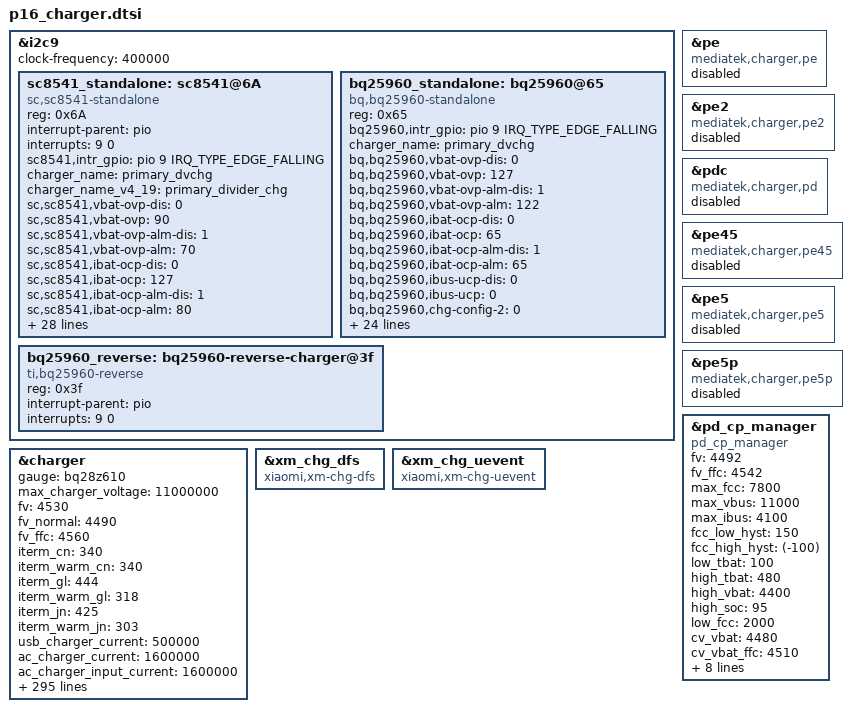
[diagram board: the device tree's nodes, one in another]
#include "mediatek/bq28z610_fg.dtsi"

&i2c9{
    clock-frequency = <400000>;
    sc8541_standalone: sc8541@6A{
        compatible = "sc,sc8541-standalone";
        #io-channel-cells = <1>;
        reg = <0x6A>;
		interrupt-parent = <&pio>;
		interrupts = <9 0>;
		sc8541,intr_gpio = <&pio 9 IRQ_TYPE_EDGE_FALLING>;
		charger_name = "primary_dvchg";
		charger_name_v4_19 = "primary_divider_chg";
		sc,sc8541,vbat-ovp-dis = <0>;
		sc,sc8541,vbat-ovp = <90>; /*3840 + val * 10*/
		sc,sc8541,vbat-ovp-alm-dis = <1>;
		sc,sc8541,vbat-ovp-alm = <70>; /*3840 + val * 10*/
		sc,sc8541,ibat-ocp-dis = <0>;
		sc,sc8541,ibat-ocp  = <127>; /*val * 100*/
		sc,sc8541,ibat-ocp-alm-dis = <1>;
		sc,sc8541,ibat-ocp-alm = <80>; /*val * 100*/
		sc,sc8541,ibus-ucp-dis = <0>;
		sc,sc8541,vbus-in-range-dis = <0>;
		sc,sc8541,vbus-pd-en = <0>;
		sc,sc8541,vbus-ovp = <127>; /*7000 + val * 50*/
		sc,sc8541,vbus-ovp-alm-dis = <1>;
		sc,sc8541,vbus-ovp-alm = <127>; /*7000 + val * 50*/
		sc,sc8541,ibus-ocp-dis = <0>;
		sc,sc8541,ibus-ocp = <21>; /*1000 + val * 250*/
		sc,sc8541,tshut-dis = <1>;
		sc,sc8541,tsbus-flt-dis = <1>;
		sc,sc8541,tsbat-flt-dis = <1>;
		sc,sc8541,tdie-alm = <200>; /*25 + val * 0.5*/
		sc,sc8541,tsbus-flt = <21>;
		sc,sc8541,tsbat-flt = <21>;
		sc,sc8541,vac1-ovp = <3>; /*0:6.5V 1:10.5V 2:12V 3:14V 4:16V 5~7:18V*/
		sc,sc8541,vac2-ovp = <3>; /*0:6.5V 1:10.5V 2:12V 3:14V 4:16V 5~7:18V*/
		sc,sc8541,vac1-pd-en = <0>;
		sc,sc8541,vac2-pd-en = <0>;
		sc,sc8541,fsw-set = <4>; /*0:200KHz 1:300KHz 2:400KHz
				3:500KHz 4:600KHz 5:650KHz 6:700KHz 7:750KHz*/
		sc,sc8541,wd-timeout = <0>; /*0:0.5s 1:1s 2:5s 3:30s*/
		sc,sc8541,wd-timeout-dis = <1>;
		sc,sc8541,ibat-sns-r = <0>; /*0:2mho 1:5mho*/
		sc,sc8541,ss-timeout = <7>; /*0:6.25ms 1:12.5ms 2:25ms 3:50ms
				4:100ms 5:400ms 6:1.5s 7:10s*/
		sc,sc8541,ibus-ucp-fall-dg = <1>;
		sc,sc8541,vout-ovp-dis = <0>;
		sc,sc8541,vout-ovp = <3>; /*4700 + val * 100*/
		sc,sc8541,pmid2out-uvp = <7>; /*50 + val * 25*/
		sc,sc8541,pmid2out-ovp = <7>; /*200 + val * 50*/
    };
    bq25960_standalone: bq25960@65 {
        compatible = "bq,bq25960-standalone";
        #io-channel-cells = <1>;
        status = "ok";
        reg = <0x65>;
        bq25960,intr_gpio = <&pio 9 IRQ_TYPE_EDGE_FALLING>;
        charger_name = "primary_dvchg";
        bq,bq25960,vbat-ovp-dis = <0>;
        bq,bq25960,vbat-ovp = <127>; /*3500 + val * 10*/
        bq,bq25960,vbat-ovp-alm-dis = <1>;
        bq,bq25960,vbat-ovp-alm = <122>; /*3500 + val * 10*/
        bq,bq25960,ibat-ocp-dis = <0>;
        bq,bq25960,ibat-ocp  = <65>; /*2000 + val * 100*/
        bq,bq25960,ibat-ocp-alm-dis = <1>;
        bq,bq25960,ibat-ocp-alm = <65>; /*2000 + val * 100*/
        bq,bq25960,ibus-ucp-dis = <0>;
        bq,bq25960,ibus-ucp = <0>;
        bq,bq25960,chg-config-2 = <0>;
        bq,bq25960,vbus-pd-en = <0>;
        bq,bq25960,vbus-ovp = <127>; /*7000 + val * 50*/
        bq,bq25960,vbus-ovp-alm-dis = <1>;
        bq,bq25960,vbus-ovp-alm = <127>; /*7000 + val * 50*/
        /*bq,bq25960,ibus-ocp-dis = <0>;*/
        bq,bq25960,ibus-ocp = <21>; /*1000 + val * 250*/
        /*bq,bq25960,tshut-dis = <1>;*/
        bq,bq25960,tshut-dis = <1>;//To be doublecheck
        bq,bq25960,tsbus-flt-dis = <1>;
        bq,bq25960,tsbat-flt-dis = <1>;
        bq,bq25960,tdie-alm = <200>; /*25 + val * 0.5*/
        bq,bq25960,tsbus-flt = <21>;
        bq,bq25960,tsbat-flt = <21>;
        bq,bq25960,vac1-ovp = <3>; /*0:6.5V 1:10.5V 2:12V 3:14V 4:16V 5~7:18V*/
        bq,bq25960,vac2-ovp = <3>; /*0:6.5V 1:10.5V 2:12V 3:14V 4:16V 5~7:18V*/
        bq,bq25960,vac1-pd-en = <0>;
        bq,bq25960,vac2-pd-en = <0>;
        bq,bq25960,fsw-set = <4>; /*0:187.5KHz 1:250KHz 2:300KHz
                                    3:375KHz 4:500KHz 5:750KHz */
        bq,bq25960,wd-timeout = <0>; /*0:0.5s 1:1s 2:5s 3:30s*/
        bq,bq25960,wd-timeout-dis = <1>;
        bq,bq25960,ibat-sns-r = <0>; /*0:2mho 1:5mho*/
        bq,bq25960,ss-timeout = <7>; /*0:6.25ms 1:12.5ms 2:25ms 3:50ms
                4:100ms 5:400ms 6:1.5s 7:10s*/
        bq,bq25960,ibus-ucp-fall-dg = <1>; /*0:0.01ms, 1:5ms, 2:50ms, 3:150ms*/
        bq,bq25960,vout-ovp-dis = <0>;
        bq,bq25960,ms = <0>;
        bq,bq25960,vout-ovp = <3>; /*4700 + val * 100*/
        /*bq,bq25960,pmid2out-uvp = <7>;*/ /*50 + val * 25*/
        /*bq,bq25960,pmid2out-ovp = <7>; */ /*150 + val * 50*/
    };

	bq25960_reverse: bq25960-reverse-charger@3f {
		status = "okay";
		#io-channel-cells = <1>;
		compatible = "ti,bq25960-reverse";
		reg = <0x3f>;
		interrupt-parent = <&pio>;
		interrupts = <9 0>;
	};
};
&pe {
	compatible = "mediatek,charger,pe";
    status = "disabled";
};
&pe2 {
    compatible = "mediatek,charger,pe2";
    status = "disabled";
};
&pdc {
    compatible = "mediatek,charger,pd";
    status = "disabled";
};
&pe45 {
    compatible = "mediatek,charger,pe45";
    status = "disabled";
};
&pe5 {
    compatible = "mediatek,charger,pe5";
    status = "disabled";
};
&pe5p {
    compatible = "mediatek,charger,pe5p";
    status = "disabled";
};
&charger {
		gauge = <&bq28z610>;
		max_charger_voltage = <11000000>;
		fv = <4530>;
		fv_normal = <4490>;
		fv_ffc = <4560>;
		iterm_cn = <340>;
		iterm_warm_cn = <340>;
		iterm_gl = <444>;
		iterm_warm_gl = <318>;
		iterm_jn = <425>;
		iterm_warm_jn = <303>;
		/* charging current */
		usb_charger_current = <500000>;
		ac_charger_current = <1600000>;
		ac_charger_input_current = <1600000>;
		charging_host_charger_current = <900000>;
		ffc_low_tbat = <230>;
		ffc_medium_tbat = <230>;
		ffc_warm_tbat = <350>;
		ffc_little_high_tbat = <400>;
		ffc_high_tbat = <450>;
		ffc_high_soc = <95>;
		step_fallback_hyst = <25>;
		step_forward_hyst = <5>;
		jeita_fallback_hyst = <10>;
		jeita_forward_hyst = <0>;
		min_charger_voltage_1 = <4600000>;
		min_charger_voltage_2 = <4500000>;
		mt6369_moscon1_control;
		disable-aicl = <1>;

		/* battery temperature protection */
		enable-min-charge-temp;
		min-charge-temp = <(-10)>;
		min-charge-temp-plus-x-degree = <(-8)>;
		max-charge-temp = <58>;
		max-charge-temp-minus-x-degree = <56>;

		en_floatgnd;

		jeita_fcc_cfg_cn = <(-100)	30	0	680	680
				31	80	4200	1360	1020
				81	130	4200	2040	1360
				131	180	4200	4760	3400
				181	230	0	5440	5440
				231	450	4070	8000	5400
				451	600	4100	3400	0>;

		jeita_fv_cfg_cn = <(-100)	30	4530
				31	80	4530
				81	130	4530
				131	180	4530
				181	230	4530
				231	450	4490
				451	600	4100>;
		/* 1-100cls */
		step_chg_cfg_1_cycle_cn_nvt = <2000	4100	8000
					4101	4200	6000
					4201	4560	5400>;
		step_chg_cfg_1_cycle_normal_cn_nvt = <2000	4070	8000
					4071	4490	5400
					4071	4490	5400>;
		step_chg_cfg_1_cycle_cn_swd = <2000	4070	8000
					4071	4170	6000
					4171	4560	5400>;
		step_chg_cfg_1_cycle_normal_cn_swd = <2000	4070	8000
					4071	4490	5400
					4071	4490	5400>;
		step_chg_cfg_1_cycle_cn_cos = <2000	4070	8000
					4071	4170	6000
					4171	4560	5400>;
		step_chg_cfg_1_cycle_normal_cn_cos = <2000	4070	8000
					4071	4490	5400
					4071	4490	5400>;
                supplement_charge_ffc_1_cycle_cn = <5440 4490 340>;
		iterm_ffc_1_cycle_cn_nvt = <340>;
		iterm_ffc_little_warm_1_cycle_cn_nvt = <1035>;
		iterm_ffc_warm_1_cycle_cn_nvt = <1518>;
		iterm_ffc_hot_1_cycle_cn_nvt = <2070>;
		iterm_ffc_1_cycle_cn_swd = <340>;
		iterm_ffc_little_warm_1_cycle_cn_swd = <1020>;
		iterm_ffc_warm_1_cycle_cn_swd = <1632>;
		iterm_ffc_hot_1_cycle_cn_swd = <2312>;
		iterm_ffc_1_cycle_cn_cos = <340>;
		iterm_ffc_little_warm_1_cycle_cn_cos = <952>;
		iterm_ffc_warm_1_cycle_cn_cos = <1428>;
		iterm_ffc_hot_1_cycle_cn_cos = <1904>;
		/* 100-300cls */
		step_chg_cfg_100_cycle_cn_nvt = <2000	4050	8000
					4051	4150	6000
					4151	4540	5400>;
		step_chg_cfg_100_cycle_normal_cn_nvt = <2000	4020	8000
					4021	4480	5400
					4021	4480	5400>;
		step_chg_cfg_100_cycle_cn_swd = <2000	4020	8000
					4021	4120	6000
					4121	4540	5400>;
		step_chg_cfg_100_cycle_normal_cn_swd = <2000	4020	8000
					4021	4480	5400
					4021	4480	5400>;
		step_chg_cfg_100_cycle_cn_cos = <2000	4020	8000
					4021	4120	6000
					4121	4540	5400>;
		step_chg_cfg_100_cycle_normal_cn_cos = <2000	4020	8000
					4021	4480	5400
					4021	4480	5400>;
		supplement_charge_ffc_100_cycle_cn = <5440 4480 340>;
		iterm_ffc_100_cycle_cn_nvt = <340>;
		iterm_ffc_little_warm_100_cycle_cn_nvt = <1035>;
		iterm_ffc_warm_100_cycle_cn_nvt = <1518>;
		iterm_ffc_hot_100_cycle_cn_nvt = <2070>;
		iterm_ffc_100_cycle_cn_swd = <340>;
		iterm_ffc_little_warm_100_cycle_cn_swd = <1020>;
		iterm_ffc_warm_100_cycle_cn_swd = <1632>;
		iterm_ffc_hot_100_cycle_cn_swd = <2312>;
		iterm_ffc_100_cycle_cn_cos = <340>;
		iterm_ffc_little_warm_100_cycle_cn_cos = <952>;
		iterm_ffc_warm_100_cycle_cn_cos = <1428>;
		iterm_ffc_hot_100_cycle_cn_cos = <1904>;
		/* 300-800cls */
		step_chg_cfg_300_cycle_cn_nvt = <2000	4020	8000
					4021	4120	6000
					4121	4520	5400>;
		step_chg_cfg_300_cycle_normal_cn_nvt = <2000	3990	8000
					3991	4470	5400
					3991	4470	5400>;
		step_chg_cfg_300_cycle_cn_swd = <2000	3990	8000
					3991	4090	6000
					4091	4520	5400>;
		step_chg_cfg_300_cycle_normal_cn_swd = <2000	3990	8000
					3991	4470	5400
					3991	4470	5400>;
		step_chg_cfg_300_cycle_cn_cos = <2000	3990	8000
					3991	4090	6000
					4091	4520	5400>;
		step_chg_cfg_300_cycle_normal_cn_cos = <2000	3990	8000
					3991	4470	5400
					3991	4470	5400>;
		supplement_charge_ffc_300_cycle_cn = <5440 4470 340>;
		iterm_ffc_300_cycle_cn_nvt = <340>;
		iterm_ffc_little_warm_300_cycle_cn_nvt = <1035>;
		iterm_ffc_warm_300_cycle_cn_nvt = <1518>;
		iterm_ffc_hot_300_cycle_cn_nvt = <2070>;
		iterm_ffc_300_cycle_cn_swd = <340>;
		iterm_ffc_little_warm_300_cycle_cn_swd = <1020>;
		iterm_ffc_warm_300_cycle_cn_swd = <1632>;
		iterm_ffc_hot_300_cycle_cn_swd = <2312>;
		iterm_ffc_300_cycle_cn_cos = <340>;
		iterm_ffc_little_warm_300_cycle_cn_cos = <952>;
		iterm_ffc_warm_300_cycle_cn_cos = <1428>;
		iterm_ffc_hot_300_cycle_cn_cos = <1904>;
		/* 800cls */
		step_chg_cfg_800_cycle_cn_nvt = <2000	4000	6400
					4001	4100	4800
					4101	4510	4320>;
		step_chg_cfg_800_cycle_normal_cn_nvt = <2000	3970	6400
					3971	4450	4320
					3971	4450	4320>;
		step_chg_cfg_800_cycle_cn_swd = <2000	3970	6400
					3971	4070	4800
					4071	4510	4320>;
		step_chg_cfg_800_cycle_normal_cn_swd = <2000	3970	6400
					3971	4450	4320
					3971	4450	4320>;
		step_chg_cfg_800_cycle_cn_cos = <2000	3970	6400
					3971	4070	4800
					4071	4510	4320>;
		step_chg_cfg_800_cycle_normal_cn_cos = <2000	3970	6400
					3971	4450	4320
					3971	4450	4320>;
		supplement_charge_ffc_800_cycle_cn = <5440 4450 340>;
		iterm_ffc_800_cycle_cn_nvt = <340>;
		iterm_ffc_little_warm_800_cycle_cn_nvt = <1035>;
		iterm_ffc_warm_800_cycle_cn_nvt = <1518>;
		iterm_ffc_hot_800_cycle_cn_nvt = <2070>;
		iterm_ffc_800_cycle_cn_swd = <340>;
		iterm_ffc_little_warm_800_cycle_cn_swd = <1020>;
		iterm_ffc_warm_800_cycle_cn_swd = <1632>;
		iterm_ffc_hot_800_cycle_cn_swd = <2312>;
		iterm_ffc_800_cycle_cn_cos = <340>;
		iterm_ffc_little_warm_800_cycle_cn_cos = <952>;
		iterm_ffc_warm_800_cycle_cn_cos = <1428>;
		iterm_ffc_hot_800_cycle_cn_cos = <1904>;

		jeita_fcc_cfg_gl = <(-100)	30	0	636	636
				31	80	4200	1270	952
				81	130	4200	1906	1270
				131	180	4200	4446	3176
				181	230	0	5080	5080
				231	450	4100	8000	5080
				451	600	4100	3176	0>;

		jeita_fv_cfg_gl = <(-100)	30	4530
				31	80	4530
				81	130	4530
				131	180	4530
				181	230	4530
				231	450	4490
				451	600	4100>;
		/* 1-100cls */
		step_chg_cfg_1_cycle_gl_nvt = <2000	4100	8000
					4101	4240	6000
					4241	4560	5080>;
		step_chg_cfg_1_cycle_normal_gl_nvt = <2000	4100	8000
					4101	4490	5080
					4101	4490	5080>;
		step_chg_cfg_1_cycle_gl_swd = <2000	4100	8000
					4101	4200	6000
					4201	4560	5080>;
		step_chg_cfg_1_cycle_normal_gl_swd = <2000	4100	8000
					4101	4490	5080
					4101	4490	5080>;
		step_chg_cfg_1_cycle_gl_cos = <2000	4100	8000
					4101	4200	6000
					4201	4560	5080>;
		step_chg_cfg_1_cycle_normal_gl_cos = <2000	4100	8000
					4101	4490	5080
					4101	4490	5080>;
		supplement_charge_ffc_1_cycle_gl = <5080 4490 444>;
		iterm_ffc_1_cycle_gl_nvt = <444>;
		iterm_ffc_little_warm_1_cycle_gl_nvt = <1162>;
		iterm_ffc_warm_1_cycle_gl_nvt = <1806>;
		iterm_ffc_hot_1_cycle_gl_nvt = <2452>;
		iterm_ffc_1_cycle_gl_swd = <444>;
		iterm_ffc_little_warm_1_cycle_gl_swd = <1080>;
		iterm_ffc_warm_1_cycle_gl_swd = <1714>;
		iterm_ffc_hot_1_cycle_gl_swd = <2350>;
		iterm_ffc_1_cycle_gl_cos = <444>;
		iterm_ffc_little_warm_1_cycle_gl_cos = <952>;
		iterm_ffc_warm_1_cycle_gl_cos = <1460>;
		iterm_ffc_hot_1_cycle_gl_cos = <1968>;
		/* 100-300cls */
		step_chg_cfg_100_cycle_gl_nvt = <2000	4050	8000
					4051	4190	6000
					4191	4540	5080>;
		step_chg_cfg_100_cycle_normal_gl_nvt = <2000	4050	8000
					4051	4480	5080
					4051	4480	5080>;
		step_chg_cfg_100_cycle_gl_swd = <2000	4050	8000
					4051	4150	6000
					4151	4540	5080>;
		step_chg_cfg_100_cycle_normal_gl_swd = <2000	4050	8000
					4051	4480	5080
					4051	4480	5080>;
		step_chg_cfg_100_cycle_gl_cos = <2000	4050	8000
					4051	4150	6000
					4151	4540	5080>;
		step_chg_cfg_100_cycle_normal_gl_cos = <2000	4050	8000
					4051	4480	5080
					4051	4480	5080>;
		supplement_charge_ffc_100_cycle_gl = <5080 4480 444>;
		iterm_ffc_100_cycle_gl_nvt = <444>;
		iterm_ffc_little_warm_100_cycle_gl_nvt = <1162>;
		iterm_ffc_warm_100_cycle_gl_nvt = <1806>;
		iterm_ffc_hot_100_cycle_gl_nvt = <2452>;
		iterm_ffc_100_cycle_gl_swd = <444>;
		iterm_ffc_little_warm_100_cycle_gl_swd = <1080>;
		iterm_ffc_warm_100_cycle_gl_swd = <1714>;
		iterm_ffc_hot_100_cycle_gl_swd = <2350>;
		iterm_ffc_100_cycle_gl_cos = <444>;
		iterm_ffc_little_warm_100_cycle_gl_cos = <952>;
		iterm_ffc_warm_100_cycle_gl_cos = <1460>;
		iterm_ffc_hot_100_cycle_gl_cos = <1968>;
		/* 300-800cls */
		step_chg_cfg_300_cycle_gl_nvt = <2000	4020	8000
					4021	4160	6000
					4161	4520	5080>;
		step_chg_cfg_300_cycle_normal_gl_nvt = <2000	4020	8000
					4021	4470	5080
					4021	4470	5080>;
		step_chg_cfg_300_cycle_gl_swd = <2000	4020	8000
					4021	4120	6000
					4121	4520	5080>;
		step_chg_cfg_300_cycle_normal_gl_swd = <2000	4020	8000
					4021	4470	5080
					4021	4470	5080>;
		step_chg_cfg_300_cycle_gl_cos = <2000	4020	8000
					4021	4120	6000
					4121	4520	5080>;
		step_chg_cfg_300_cycle_normal_gl_cos = <2000	4020	8000
					4021	4470	5080
					4021	4470	5080>;
		supplement_charge_ffc_300_cycle_gl = <5080 4450 444>;
		iterm_ffc_300_cycle_gl_nvt = <444>;
		iterm_ffc_little_warm_300_cycle_gl_nvt = <1162>;
		iterm_ffc_warm_300_cycle_gl_nvt = <1806>;
		iterm_ffc_hot_300_cycle_gl_nvt = <2452>;
		iterm_ffc_300_cycle_gl_swd = <444>;
		iterm_ffc_little_warm_300_cycle_gl_swd = <1080>;
		iterm_ffc_warm_300_cycle_gl_swd = <1714>;
		iterm_ffc_hot_300_cycle_gl_swd = <2350>;
		iterm_ffc_300_cycle_gl_cos = <444>;
		iterm_ffc_little_warm_300_cycle_gl_cos = <952>;
		iterm_ffc_warm_300_cycle_gl_cos = <1460>;
		iterm_ffc_hot_300_cycle_gl_cos = <1968>;
		/* 800cls */
		step_chg_cfg_800_cycle_gl_nvt = <2000	4000	6400
					4001	4140	4800
					4141	4510	4064>;
		step_chg_cfg_800_cycle_normal_gl_nvt = <2000	4000	6400
					4001	4450	4064
					4001	4450	4064>;
		step_chg_cfg_800_cycle_gl_swd = <2000	4000	6400
					4001	4100	4800
					4101	4510	4064>;
		step_chg_cfg_800_cycle_normal_gl_swd = <2000	4000	6400
					4001	4450	4064
					4001	4450	4064>;
		step_chg_cfg_800_cycle_gl_cos = <2000	4000	6400
					4001	4100	4800
					4101	4510	4064>;
		step_chg_cfg_800_cycle_normal_gl_cos = <2000	4000	6400
					4001	4450	4064
					4001	4450	4064>;
		supplement_charge_ffc_800_cycle_gl = <5080 4450 444>;
		iterm_ffc_800_cycle_gl_nvt = <444>;
		iterm_ffc_little_warm_800_cycle_gl_nvt = <1162>;
		iterm_ffc_warm_800_cycle_gl_nvt = <1806>;
		iterm_ffc_hot_800_cycle_gl_nvt = <2452>;
		iterm_ffc_800_cycle_gl_swd = <444>;
		iterm_ffc_little_warm_800_cycle_gl_swd = <1080>;
		iterm_ffc_warm_800_cycle_gl_swd = <1714>;
		iterm_ffc_hot_800_cycle_gl_swd = <2350>;
		iterm_ffc_800_cycle_gl_cos = <444>;
		iterm_ffc_little_warm_800_cycle_gl_cos = <952>;
		iterm_ffc_warm_800_cycle_gl_cos = <1460>;
		iterm_ffc_hot_800_cycle_gl_cos = <1968>;

		jeita_fcc_cfg_jn = <(-100)	30	0	607	607
				31	80	4200	1214	911
				81	130	4200	1821	1214
				131	180	4200	4249	3035
				181	230	0	4856	4856
				231	450	4100	8000	4856
				451	600	4100	3035	0>;

		jeita_fv_cfg_jn = <(-100)	30	4530
				31	80	4530
				81	130	4530
				131	180	4530
				181	230	4530
				231	450	4490
				451	600	4100>;
		/* 1-100cls */
		step_chg_cfg_1_cycle_jn_nvt = <2000	4100	8000
					4101	4240	6000
					4241	4560	4856>;
		step_chg_cfg_1_cycle_normal_jn_nvt = <2000	4100	8000
					4101	4490	4856
					4101	4490	4856>;
		supplement_charge_ffc_1_cycle_jn = <4856 4490 432>;
		iterm_ffc_1_cycle_jn_nvt = <432>;
		iterm_ffc_little_warm_1_cycle_jn_nvt = <1480>;
		iterm_ffc_warm_1_cycle_jn_nvt = <1790>;
		iterm_ffc_hot_1_cycle_jn_nvt = <2468>;
		/* 100-300cls */
		step_chg_cfg_100_cycle_jn_nvt = <2000	4040	8000
					4041	4190	6000
					4191	4540	4856>;
		step_chg_cfg_100_cycle_normal_jn_nvt = <2000	4050	8000
					4051	4480	4856
					4051	4480	4856>;
		supplement_charge_ffc_100_cycle_jn = <4856 4480 432>;
		iterm_ffc_100_cycle_jn_nvt = <432>;
		iterm_ffc_little_warm_100_cycle_jn_nvt = <1480>;
		iterm_ffc_warm_100_cycle_jn_nvt = <1790>;
		iterm_ffc_hot_100_cycle_jn_nvt = <2468>;
		/* 300-800cls */
		step_chg_cfg_300_cycle_jn_nvt = <2000	4020	8000
					4021	4160	6000
					4161	4520	4856>;
		step_chg_cfg_300_cycle_normal_jn_nvt = <2000	4020	8000
					4021	4470	4856
					4021	4470	4856>;
		supplement_charge_ffc_300_cycle_jn = <4856 4470 432>;
		iterm_ffc_300_cycle_jn_nvt = <432>;
		iterm_ffc_little_warm_300_cycle_jn_nvt = <1480>;
		iterm_ffc_warm_300_cycle_jn_nvt = <1790>;
		iterm_ffc_hot_300_cycle_jn_nvt = <2468>;
		/* 800cls */
		step_chg_cfg_800_cycle_jn_nvt = <2000	4000	6400
					4001	4140	4800
					4141	4510	3884>;
		step_chg_cfg_800_cycle_normal_jn_nvt = <2000	4000	6400
					4001	4450	3884
					4001	4450	3884>;
		supplement_charge_ffc_800_cycle_jn = <4856 4450 432>;
		iterm_ffc_800_cycle_jn_nvt = <432>;
		iterm_ffc_little_warm_800_cycle_jn_nvt = <1480>;
		iterm_ffc_warm_800_cycle_jn_nvt = <1790>;
		iterm_ffc_hot_800_cycle_jn_nvt = <2468>;
		thermal_limit_dcp = <2000 2000 2000 2000 2000 2000
				     2000 2000 2000 2000 2000 2000
				     2000 2000 2000 2000 2000 2000
				     2000 2000 2000 2000 2000 2000
				     2000 2000 2000 2000 2000 2000
				     2000 1800 1600 1400 1000 500>;
		thermal_limit_qc2 = <4000 4000 4000 4000 4000 4000
				     3000 3000 3000 3000 3000 3000
				     2000 2000 2000 2000 2000 2000
				     2000 2000 2000 2000 2000 2000
				     2000 2000 2000 2000 2000 2000
				     2000 1800 1600 1400 1000 500>;
		thermal_limit_qc3_18w = <4000 4000 4000 4000 4000 4000
				     3000 3000 3000 3000 3000 3000
				     2000 2000 2000 2000 2000 2000
				     2000 2000 2000 2000 2000 2000
				     2000 2000 2000 2000 2000 2000
				     2000 1800 1600 1400 1000 500>;
		thermal_limit_qc3_27w = <6000 6000 6000 6000 6000 6000
					 5000 5000 5000 5000 5000 5000
					 4000 4000 4000 4000 4000 4000
					 3000 3000 3000 3000 3000 3000
					 2000 2000 2000 2000 2000 2000
					 2000 1800 1600 1400 1000 500>;
		thermal_limit_qc35 = <4000 4000 4000 4000 4000 4000
				     3000 3000 3000 3000 3000 3000
				     2000 2000 2000 2000 2000 2000
				     2000 2000 2000 2000 2000 2000
				     2000 2000 2000 2000 2000 2000
				     2000 1800 1600 1400 1000 500>;
		thermal_limit_pd = <8000 7800 7600 7400 7200 7000
				    6800 6600 6400 6200 6000 5800
				    5600 5400 5200 5000 4800 4600
				    4400 4200 4000 3800 3600 3400
				    3200 3000 2800 2600 2400 2200
				    2000 1800 1600 1400 1000 500>;
		thermal_limit_smartchg = <8000 8000 7800 7600 7400 7200
					7000 6800 6600 6400 6200 6000
					5800 5600 5400 5200 5000 4800
					4600 4400 4200 4000 3800 3600
					3400 3200 3000 2800 2600 2400
					2200 2000 1800 1600 1400 1000>;
};
&pd_cp_manager {
		compatible = "pd_cp_manager";
		fv = <4492>;
		fv_ffc = <4542>;
		max_fcc = <7800>;
		max_vbus = <11000>;
		max_ibus = <4100>;
		fcc_low_hyst = <150>;
		fcc_high_hyst = <(-100)>;
		low_tbat = <100>;
		high_tbat = <480>;
		high_vbat = <4400>;
		high_soc = <95>;
		low_fcc = <2000>;
		cv_vbat = <4480>;
		cv_vbat_ffc = <4510>;
		cv_ibat = <1200>;
		min_pdo_vbus = <8000>;
		max_pdo_vbus = <11000>;
		//mt6375_control_gpio = <&pio 215 0x0>;
		//support_4_1_mode;
		switch1_1_enter = <2600>;
		switch1_1_exit = <3600>;
		switch2_1_enter = <6000>;
		switch2_1_exit = <7000>;
		pdm_ibus_gap = <600>;
};

&xm_chg_dfs {
		compatible = "xiaomi,xm-chg-dfs";
		status = "okay";
};

&xm_chg_uevent {
		compatible = "xiaomi,xm-chg-uevent";
		status = "okay";
};
